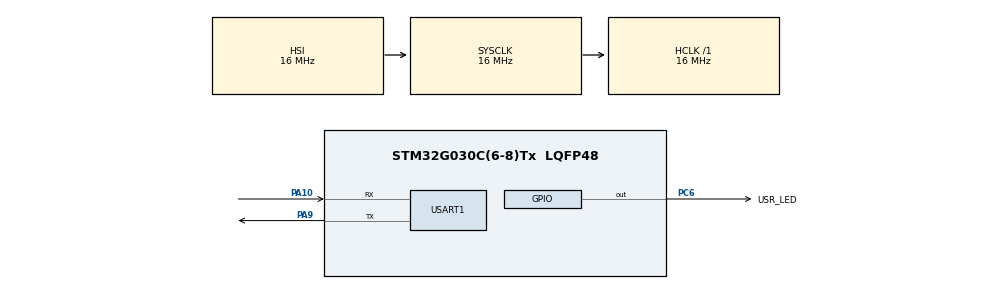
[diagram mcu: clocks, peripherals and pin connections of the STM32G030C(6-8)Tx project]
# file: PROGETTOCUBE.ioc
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Mcu.Family=STM32G0
Mcu.Name=STM32G030C(6-8)Tx
Mcu.Package=LQFP48
NVIC.USART1_IRQn=true\:0\:0\:false\:false\:true\:true\:true\:true
PA10.Mode=Asynchronous
PA10.Signal=USART1_RX
PA13.Mode=Serial_Wire
PA13.Signal=SYS_SWDIO
PA14-BOOT0.Mode=Serial_Wire
PA14-BOOT0.Signal=SYS_SWCLK
PA9.Mode=Asynchronous
PA9.Signal=USART1_TX
PC14-OSC32_IN\ (PC14).Mode=LSE-External-Oscillator
PC14-OSC32_IN\ (PC14).Signal=RCC_OSC32_IN
PC15-OSC32_OUT\ (PC15).Mode=LSE-External-Oscillator
PC15-OSC32_OUT\ (PC15).Signal=RCC_OSC32_OUT
PC6.GPIO_Label=USR_LED
PC6.Signal=GPIO_Output
PF0-OSC_IN\ (PF0).Mode=HSE-External-Oscillator
PF0-OSC_IN\ (PF0).Signal=RCC_OSC_IN
PF1-OSC_OUT\ (PF1).Mode=HSE-External-Oscillator
PF1-OSC_OUT\ (PF1).Signal=RCC_OSC_OUT
ProjectManager.HeapSize=0x200
ProjectManager.StackSize=0x400
ProjectManager.TargetToolchain=STM32CubeIDE
RCC.AHBFreq_Value=16000000
RCC.CortexFreq_Value=16000000
RCC.EXTERNAL_CLOCK_VALUE=12288000
RCC.HCLKFreq_Value=16000000
RCC.HSE_VALUE=8000000
RCC.HSI_VALUE=16000000
RCC.PLLN=12
RCC.PLLSourceVirtual=RCC_PLLSOURCE_HSE
RCC.SYSCLKFreq_VALUE=16000000
RCC.VCOOutputFreq_Value=96000000
USART1.VirtualMode-Asynchronous=VM_ASYNC
board=custom

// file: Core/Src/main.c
/* USER CODE BEGIN Header */
/**
  ******************************************************************************
  * @file           : main.c
  * @brief          : Main program body
  ******************************************************************************
  * @attention
  *
  * Copyright (c) 2026 STMicroelectronics.
  * All rights reserved.
  *
  * This software is licensed under terms that can be found in the LICENSE file
  * in the root directory of this software component.
  * If no LICENSE file comes with this software, it is provided AS-IS.
  *
  ******************************************************************************
  */
/* USER CODE END Header */
#include "main.h"

UART_HandleTypeDef huart1;

/* USER CODE BEGIN PV */
char tx_data[]= "Seleziona la frequenza di lampeggio: 1,2 o 3 \r\n";
char rx_data[2];  /* +1 byte per il null terminator */
volatile uint32_t blink_period_ms = 0;   /* 0 = led spento */
uint32_t last_toggle_tick = 0;
/* USER CODE END PV */

void SystemClock_Config(void);
static void MX_GPIO_Init(void);
static void MX_USART1_UART_Init(void);

int main(void)
{

  /* MCU Configuration--------------------------------------------------------*/

  /* Reset of all peripherals, Initializes the Flash interface and the Systick. */
  HAL_Init();

  /* Configure the system clock */
  SystemClock_Config();

  /* Initialize all configured peripherals */
  MX_GPIO_Init();
  MX_USART1_UART_Init();
  /* USER CODE BEGIN 2 */
  HAL_UART_Transmit(&huart1, (uint8_t*)tx_data, sizeof(tx_data)-1, HAL_MAX_DELAY);
  HAL_UART_Receive_IT(&huart1, (uint8_t*)rx_data, 1);
  /* USER CODE END 2 */

  /* Infinite loop */
  while (1)
  {

    /* USER CODE BEGIN 3 */
	if (blink_period_ms > 0)
	{
	    uint32_t now = HAL_GetTick();
	    if ((now - last_toggle_tick) >= blink_period_ms)
	    {
	        HAL_GPIO_TogglePin(USR_LED_GPIO_Port, USR_LED_Pin);
	        last_toggle_tick = now;
	    }
	}
	else
	{
	    HAL_GPIO_WritePin(USR_LED_GPIO_Port, USR_LED_Pin, GPIO_PIN_RESET);
	}
  }
  /* USER CODE END 3 */
}

void SystemClock_Config(void)
{
  RCC_OscInitTypeDef RCC_OscInitStruct = {0};
  RCC_ClkInitTypeDef RCC_ClkInitStruct = {0};

  /** Configure the main internal regulator output voltage
  */
  HAL_PWREx_ControlVoltageScaling(PWR_REGULATOR_VOLTAGE_SCALE1);

  /** Initializes the RCC Oscillators according to the specified parameters
  * in the RCC_OscInitTypeDef structure.
  */
  RCC_OscInitStruct.OscillatorType = RCC_OSCILLATORTYPE_HSI;
  RCC_OscInitStruct.HSIState = RCC_HSI_ON;
  RCC_OscInitStruct.HSIDiv = RCC_HSI_DIV1;
  RCC_OscInitStruct.HSICalibrationValue = RCC_HSICALIBRATION_DEFAULT;
  RCC_OscInitStruct.PLL.PLLState = RCC_PLL_NONE;
  if (HAL_RCC_OscConfig(&RCC_OscInitStruct) != HAL_OK)
  {
    Error_Handler();
  }

  /** Initializes the CPU, AHB and APB buses clocks
  */
  RCC_ClkInitStruct.ClockType = RCC_CLOCKTYPE_HCLK|RCC_CLOCKTYPE_SYSCLK
                              |RCC_CLOCKTYPE_PCLK1;
  RCC_ClkInitStruct.SYSCLKSource = RCC_SYSCLKSOURCE_HSI;
  RCC_ClkInitStruct.AHBCLKDivider = RCC_SYSCLK_DIV1;
  RCC_ClkInitStruct.APB1CLKDivider = RCC_HCLK_DIV1;

  if (HAL_RCC_ClockConfig(&RCC_ClkInitStruct, FLASH_LATENCY_0) != HAL_OK)
  {
    Error_Handler();
  }
}

static void MX_USART1_UART_Init(void)
{

  huart1.Instance = USART1;
  huart1.Init.BaudRate = 115200;
  huart1.Init.WordLength = UART_WORDLENGTH_8B;
  huart1.Init.StopBits = UART_STOPBITS_1;
  huart1.Init.Parity = UART_PARITY_NONE;
  huart1.Init.Mode = UART_MODE_TX_RX;
  huart1.Init.HwFlowCtl = UART_HWCONTROL_NONE;
  huart1.Init.OverSampling = UART_OVERSAMPLING_16;
  huart1.Init.OneBitSampling = UART_ONE_BIT_SAMPLE_DISABLE;
  huart1.Init.ClockPrescaler = UART_PRESCALER_DIV1;
  huart1.AdvancedInit.AdvFeatureInit = UART_ADVFEATURE_NO_INIT;
  if (HAL_UART_Init(&huart1) != HAL_OK)
  {
    Error_Handler();
  }
  if (HAL_UARTEx_SetTxFifoThreshold(&huart1, UART_TXFIFO_THRESHOLD_1_8) != HAL_OK)
  {
    Error_Handler();
  }
  if (HAL_UARTEx_SetRxFifoThreshold(&huart1, UART_RXFIFO_THRESHOLD_1_8) != HAL_OK)
  {
    Error_Handler();
  }
  if (HAL_UARTEx_DisableFifoMode(&huart1) != HAL_OK)
  {
    Error_Handler();
  }

}

static void MX_GPIO_Init(void)
{
  GPIO_InitTypeDef GPIO_InitStruct = {0};

  /* GPIO Ports Clock Enable */
  __HAL_RCC_GPIOC_CLK_ENABLE();
  __HAL_RCC_GPIOF_CLK_ENABLE();
  __HAL_RCC_GPIOA_CLK_ENABLE();

  /*Configure GPIO pin Output Level */
  HAL_GPIO_WritePin(USR_LED_GPIO_Port, USR_LED_Pin, GPIO_PIN_RESET);

  /*Configure GPIO pin : USR_LED_Pin */
  GPIO_InitStruct.Pin = USR_LED_Pin;
  GPIO_InitStruct.Mode = GPIO_MODE_OUTPUT_PP;
  GPIO_InitStruct.Pull = GPIO_NOPULL;
  GPIO_InitStruct.Speed = GPIO_SPEED_FREQ_LOW;
  HAL_GPIO_Init(USR_LED_GPIO_Port, &GPIO_InitStruct);

}

/* USER CODE BEGIN 4 */
void HAL_UART_RxCpltCallback(UART_HandleTypeDef *huart)
{
  /* Prevent unused argument(s) compilation warning */
  UNUSED(huart);

  /* NOTE : This function should not be modified, when the callback is needed,
            the HAL_UART_RxCpltCallback can be implemented in the user file.
   */
  /* Echo del carattere ricevuto */
    HAL_UART_Transmit(&huart1, (uint8_t*)rx_data, 1, HAL_MAX_DELAY);

    if (rx_data[0] == '1') {
        blink_period_ms = 500;   /* toggle ogni 500ms → periodo completo 1s */
    }
    else if (rx_data[0] == '2') {
        blink_period_ms = 200;   /* toggle ogni 200ms → periodo completo 400ms */
    }
    else if (rx_data[0] == '3') {
        blink_period_ms = 25;    /* toggle ogni 25ms  → periodo completo 50ms */
    }

    /* Riarma la ricezione per il prossimo byte */
    HAL_UART_Receive_IT(&huart1, (uint8_t*)rx_data, 1);
}
/* USER CODE END 4 */

void Error_Handler(void)
{
  __disable_irq();
  while (1)
  {
  }
}
